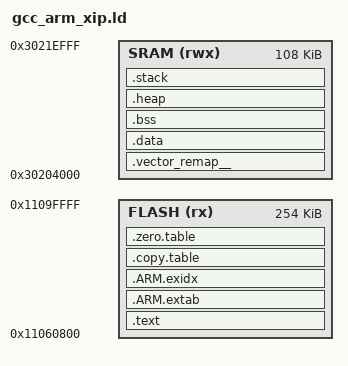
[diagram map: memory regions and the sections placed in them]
/* SPDX-License-Identifier: BSD-3-Clause */
/*
 * Copyright (c) 2020-2023 Rockchip Electronics Co., Ltd.
 */

/*
 *-------- <<< Use Configuration Wizard in Context Menu >>> -------------------
 */

/*---------------------- Flash Configuration ----------------------------------
  <h> Flash Configuration
    <o0> Flash Base Address <0x0-0xFFFFFFFF:8>
    <o1> Flash Size (in Bytes) <0x0-0xFFFFFFFF:8>
  </h>
  -----------------------------------------------------------------------------*/
__FLASH_BASE = 0x11060800;
__FLASH_SIZE = 0x0003f800;

/*--------------------- Embedded RAM Configuration ----------------------------
  <h> RAM Configuration
    <o0> RAM Base Address    <0x0-0xFFFFFFFF:8>
    <o1> RAM Size (in Bytes) <0x0-0xFFFFFFFF:8>
  </h>
 -----------------------------------------------------------------------------*/
__SRAM_BASE = 0x30204000;
__SRAM_SIZE = 0x0001b000;

/*--------------------- DRAM Configuration ----------------------------
  <h> RAM Configuration
    <o0> DRAM Base Address    <0x0-0xFFFFFFFF:8>
    <o1> DRAM Size (in Bytes) <0x0-0xFFFFFFFF:8>
  </h>
 -----------------------------------------------------------------------------*/
__DRAM_BASE = 0xa0000000;
__DRAM_SIZE = 0x04000000;

/*--------------------- Stack / Heap Configuration ----------------------------
  <h> Stack / Heap Configuration
    <o0> Stack Size (in Bytes) <0x0-0xFFFFFFFF:8>
    <o1> Heap Size (in Bytes) <0x0-0xFFFFFFFF:8>
  </h>
  -----------------------------------------------------------------------------*/
__STACK_SIZE = 0x00000400;
__HEAP_SIZE  = 0x00008000;

/*
 *-------------------- <<< end of configuration section >>> -------------------
 */

/* ARMv8-M stack sealing:
   to use ARMv8-M stack sealing set __STACKSEAL_SIZE to 8 otherwise keep 0
 */
__STACKSEAL_SIZE = 0;


MEMORY
{
  FLASH (rx)  : ORIGIN = __FLASH_BASE, LENGTH = __FLASH_SIZE
  SRAM  (rwx) : ORIGIN = __SRAM_BASE,  LENGTH = __SRAM_SIZE
}

/* Linker script to place sections and symbol values. Should be used together
 * with other linker script that defines memory regions FLASH and RAM.
 * It references following symbols, which must be defined in code:
 *   Reset_Handler : Entry of reset handler
 *
 * It defines following symbols, which code can use without definition:
 *   __exidx_start
 *   __exidx_end
 *   __copy_table_start__
 *   __copy_table_end__
 *   __zero_table_start__
 *   __zero_table_end__
 *   __etext
 *   __data_start__
 *   __preinit_array_start
 *   __preinit_array_end
 *   __init_array_start
 *   __init_array_end
 *   __fini_array_start
 *   __fini_array_end
 *   __data_end__
 *   __bss_start__
 *   __bss_end__
 *   __end__
 *   end
 *   __HeapLimit
 *   __StackLimit
 *   __StackTop
 *   __stack
 *   __StackSeal      (only if ARMv8-M stack sealing is used)
 */
ENTRY(Reset_Handler)

SECTIONS
{
  .text :
  {
    KEEP(*(.vectors))
    *(.text*)

    KEEP(*(.init))
    KEEP(*(.fini))

    /* .ctors */
    *crtbegin.o(.ctors)
    *crtbegin?.o(.ctors)
    *(EXCLUDE_FILE(*crtend?.o *crtend.o) .ctors)
    *(SORT(.ctors.*))
    *(.ctors)

    /* .dtors */
    *crtbegin.o(.dtors)
    *crtbegin?.o(.dtors)
    *(EXCLUDE_FILE(*crtend?.o *crtend.o) .dtors)
    *(SORT(.dtors.*))
    *(.dtors)

    *(.rodata*)

    KEEP(*(.eh_frame*))
  } > FLASH

  /*
   * SG veneers:
   * All SG veneers are placed in the special output section .gnu.sgstubs. Its start address
   * must be set, either with the command line option �--section-start� or in a linker script,
   * to indicate where to place these veneers in memory.
   */
/*
  .gnu.sgstubs :
  {
    . = ALIGN(32);
  } > FLASH
*/
  .ARM.extab :
  {
    *(.ARM.extab* .gnu.linkonce.armextab.*)
  } > FLASH

  __exidx_start = .;
  .ARM.exidx :
  {
    *(.ARM.exidx* .gnu.linkonce.armexidx.*)
  } > FLASH
  __exidx_end = .;

  .copy.table :
  {
    . = ALIGN(4);
    __copy_table_start__ = .;

    LONG (__Vectors)
    LONG (__vector_remap__)
    LONG (__Vectors_Size / 4)

    LONG (__etext)
    LONG (__data_start__)
    LONG ((__data_end__ - __data_start__) / 4)

    /* Add each additional data section here */
/*
    LONG (__etext2)
    LONG (__data2_start__)
    LONG ((__data2_end__ - __data2_start__) / 4)
*/
    __copy_table_end__ = .;
  } > FLASH

  .zero.table :
  {
    . = ALIGN(4);
    __zero_table_start__ = .;

    LONG (__bss_start__)
    LONG ((__bss_end__ - __bss_start__) / 4)

    /* Add each additional bss section here */
/*
    LONG (__bss2_start__)
    LONG ((__bss2_end__ - __bss2_start__) / 4)
*/
    __zero_table_end__ = .;
  } > FLASH

  /**
   * Location counter can end up 2byte aligned with narrow Thumb code but
   * __etext is assumed by startup code to be the LMA of a section in RAM
   * which must be 4byte aligned
   */
  __etext = ALIGN (4);

  .vector_remap__ (NOLOAD) :
  {
    PROVIDE(__vector_remap__ = .);
    . = . + __Vectors_Size;
  } > SRAM

  .data : AT (__etext)
  {
    __data_start__ = .;
    *(vtable)
    *(.data)
    *(.data.*)

    . = ALIGN(4);
    /* preinit data */
    PROVIDE_HIDDEN (__preinit_array_start = .);
    KEEP(*(.preinit_array))
    PROVIDE_HIDDEN (__preinit_array_end = .);

    . = ALIGN(4);
    /* init data */
    PROVIDE_HIDDEN (__init_array_start = .);
    KEEP(*(SORT(.init_array.*)))
    KEEP(*(.init_array))
    PROVIDE_HIDDEN (__init_array_end = .);

    . = ALIGN(4);
    /* finit data */
    PROVIDE_HIDDEN (__fini_array_start = .);
    KEEP(*(SORT(.fini_array.*)))
    KEEP(*(.fini_array))
    PROVIDE_HIDDEN (__fini_array_end = .);

    KEEP(*(.jcr*))
    . = ALIGN(4);
    /* All data end */
    __data_end__ = .;

  } > SRAM

  /*
   * Secondary data section, optional
   *
   * Remember to add each additional data section
   * to the .copy.table above to asure proper
   * initialization during startup.
   */
/*
  __etext2 = ALIGN (4);

  .data2 : AT (__etext2)
  {
    . = ALIGN(4);
    __data2_start__ = .;
    *(.data2)
    *(.data2.*)
    . = ALIGN(4);
    __data2_end__ = .;

  } > HYRAM
*/

  .bss :
  {
    . = ALIGN(4);
    __bss_start__ = .;
    *(.bss)
    *(.bss.*)
    *(COMMON)
    . = ALIGN(4);
    __bss_end__ = .;
  } > SRAM AT > SRAM

  /*
   * Secondary bss section, optional
   *
   * Remember to add each additional bss section
   * to the .zero.table above to asure proper
   * initialization during startup.
   */
/*
  .bss2 :
  {
    . = ALIGN(4);
    __bss2_start__ = .;
    *(.bss2)
    *(.bss2.*)
    . = ALIGN(4);
    __bss2_end__ = .;
  } > HYRAM AT > HYRAM
*/

  .heap (COPY) :
  {
    . = ALIGN(8);
    __end__ = .;
    PROVIDE(end = .);
    . = . + __HEAP_SIZE;
    . = ALIGN(8);
    __HeapLimit = .;
  } > SRAM

  .stack (ORIGIN(SRAM) + LENGTH(SRAM) - __STACK_SIZE - __STACKSEAL_SIZE) (COPY) :
  {
    . = ALIGN(8);
    __StackLimit = .;
    . = . + __STACK_SIZE;
    . = ALIGN(8);
    __StackTop = .;
  } > SRAM
  PROVIDE(__stack = __StackTop);

  /* ARMv8-M stack sealing:
     to use ARMv8-M stack sealing uncomment '.stackseal' section
   */
/*
  .stackseal (ORIGIN(RAM) + LENGTH(RAM) - __STACKSEAL_SIZE) (COPY) :
  {
    . = ALIGN(8);
    __StackSeal = .;
    . = . + 8;
    . = ALIGN(8);
  } > SRAM
*/

  /* Check if data + heap + stack exceeds RAM limit */
  ASSERT(__StackLimit >= __HeapLimit, "region RAM overflowed with stack")


   PROVIDE(__flash_start__ = ORIGIN(FLASH));
   PROVIDE(__flash_end__ = ORIGIN(FLASH) + LENGTH(FLASH) - 1);
   PROVIDE(__sram_start__ = ORIGIN(SRAM));
   PROVIDE(__sram_end__ = ORIGIN(SRAM) + LENGTH(SRAM) - 1);
   PROVIDE(__device_start__ = 0x50000000);
   PROVIDE(__device_end__ = 0x50E00000 - 1);
}
